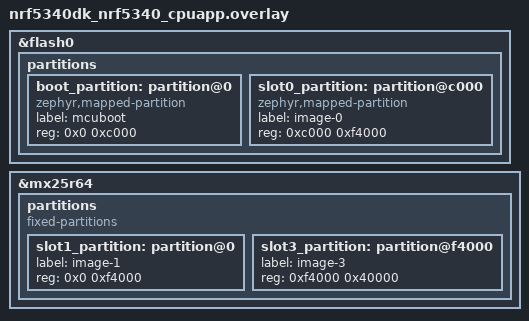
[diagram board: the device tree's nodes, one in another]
/delete-node/ &boot_partition;
/delete-node/ &slot0_partition;
/delete-node/ &slot1_partition;
/delete-node/ &storage_partition;

&flash0 {
	partitions {
		boot_partition: partition@0 {
			compatible = "zephyr,mapped-partition";
			label = "mcuboot";
			reg = <0x0 0xc000>;
		};

		slot0_partition: partition@c000 {
			compatible = "zephyr,mapped-partition";
			label = "image-0";
			reg = <0xc000 0xf4000>;
		};
	};
};

&mx25r64 {
	partitions {
		compatible = "fixed-partitions";
		#address-cells = <1>;
		#size-cells = <1>;

		slot1_partition: partition@0 {
			label = "image-1";
			reg = <0x0 0xf4000>;
		};

		slot3_partition: partition@f4000 {
			label = "image-3";
			reg = <0xf4000 0x40000>;
		};
	};
};
